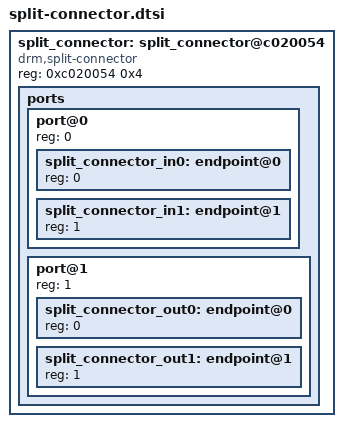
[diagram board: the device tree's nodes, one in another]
	split_connector: split_connector@c020054 {
		compatible = "drm,split-connector";
		reg = <0xc020054 0x4>;
		ports {
			#address-cells = <1>;
			#size-cells = <0>;

			port@0 {
				reg = <0>;
				#address-cells = <1>;
				#size-cells = <0>;

				split_connector_in0: endpoint@0 {
					reg = <0>;
				};
				split_connector_in1: endpoint@1 {
					reg = <1>;
				};
			};

			port@1 {
				reg = <1>;
				#address-cells = <1>;
				#size-cells = <0>;
				split_connector_out0: endpoint@0 {
					reg = <0>;
				};

				split_connector_out1: endpoint@1 {
					reg = <1>;
				};
			};
		};
	};
